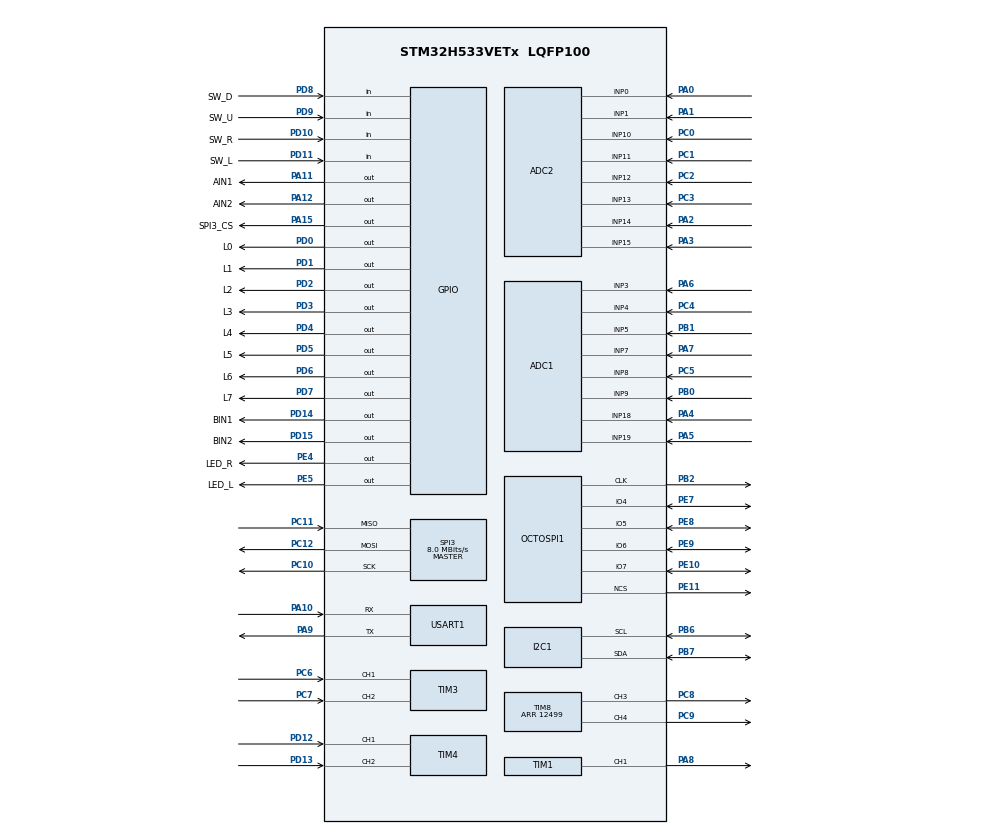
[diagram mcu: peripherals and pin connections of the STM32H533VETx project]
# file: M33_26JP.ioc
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ADC1.Channel-0\#ChannelRegularConversion=ADC_CHANNEL_5
ADC1.Channel-1\#ChannelRegularConversion=ADC_CHANNEL_9
ADC1.Channel-2\#ChannelRegularConversion=ADC_CHANNEL_8
ADC1.Channel-3\#ChannelRegularConversion=ADC_CHANNEL_4
ADC1.Channel-4\#ChannelRegularConversion=ADC_CHANNEL_7
ADC1.Channel-5\#ChannelRegularConversion=ADC_CHANNEL_3
ADC1.Channel-6\#ChannelRegularConversion=ADC_CHANNEL_19
ADC1.Channel-7\#ChannelRegularConversion=ADC_CHANNEL_18
ADC1.DiscontinuousConvMode=ENABLE
ADC1.ExternalTrigConv=ADC_EXTERNALTRIG_T2_TRGO
ADC1.MonitoredBy-0\#ChannelRegularConversion=__NULL
ADC1.MonitoredBy-1\#ChannelRegularConversion=__NULL
ADC1.MonitoredBy-2\#ChannelRegularConversion=__NULL
ADC1.MonitoredBy-3\#ChannelRegularConversion=__NULL
ADC1.MonitoredBy-4\#ChannelRegularConversion=__NULL
ADC1.MonitoredBy-5\#ChannelRegularConversion=__NULL
ADC1.MonitoredBy-6\#ChannelRegularConversion=__NULL
ADC1.MonitoredBy-7\#ChannelRegularConversion=__NULL
ADC1.NbrOfConversion=8
ADC1.NbrOfConversionFlag=1
ADC1.OffsetNumber-0\#ChannelRegularConversion=ADC_OFFSET_NONE
ADC1.OffsetNumber-1\#ChannelRegularConversion=ADC_OFFSET_NONE
ADC1.OffsetNumber-2\#ChannelRegularConversion=ADC_OFFSET_NONE
ADC1.OffsetNumber-3\#ChannelRegularConversion=ADC_OFFSET_NONE
ADC1.OffsetNumber-4\#ChannelRegularConversion=ADC_OFFSET_NONE
ADC1.OffsetNumber-5\#ChannelRegularConversion=ADC_OFFSET_NONE
ADC1.OffsetNumber-6\#ChannelRegularConversion=ADC_OFFSET_NONE
ADC1.OffsetNumber-7\#ChannelRegularConversion=ADC_OFFSET_NONE
ADC1.Rank-0\#ChannelRegularConversion=1
ADC1.Rank-1\#ChannelRegularConversion=2
ADC1.Rank-2\#ChannelRegularConversion=3
ADC1.Rank-3\#ChannelRegularConversion=4
ADC1.Rank-4\#ChannelRegularConversion=5
ADC1.Rank-5\#ChannelRegularConversion=6
ADC1.Rank-6\#ChannelRegularConversion=7
ADC1.Rank-7\#ChannelRegularConversion=8
ADC1.SamplingTime-0\#ChannelRegularConversion=ADC_SAMPLETIME_6CYCLES_5
ADC1.SamplingTime-1\#ChannelRegularConversion=ADC_SAMPLETIME_6CYCLES_5
ADC1.SamplingTime-2\#ChannelRegularConversion=ADC_SAMPLETIME_6CYCLES_5
ADC1.SamplingTime-3\#ChannelRegularConversion=ADC_SAMPLETIME_6CYCLES_5
ADC1.SamplingTime-4\#ChannelRegularConversion=ADC_SAMPLETIME_6CYCLES_5
ADC1.SamplingTime-5\#ChannelRegularConversion=ADC_SAMPLETIME_6CYCLES_5
ADC1.SamplingTime-6\#ChannelRegularConversion=ADC_SAMPLETIME_6CYCLES_5
ADC1.SamplingTime-7\#ChannelRegularConversion=ADC_SAMPLETIME_6CYCLES_5
ADC1.master=1
ADC2.Channel-2\#ChannelRegularConversion=ADC_CHANNEL_15
ADC2.Channel-3\#ChannelRegularConversion=ADC_CHANNEL_14
ADC2.Channel-4\#ChannelRegularConversion=ADC_CHANNEL_1
ADC2.Channel-5\#ChannelRegularConversion=ADC_CHANNEL_0
ADC2.Channel-6\#ChannelRegularConversion=ADC_CHANNEL_13
ADC2.Channel-7\#ChannelRegularConversion=ADC_CHANNEL_12
ADC2.Channel-8\#ChannelRegularConversion=ADC_CHANNEL_11
ADC2.Channel-9\#ChannelRegularConversion=ADC_CHANNEL_10
ADC2.DiscontinuousConvMode=ENABLE
ADC2.ExternalTrigConv=ADC_EXTERNALTRIG_T2_TRGO
ADC2.MonitoredBy-2\#ChannelRegularConversion=__NULL
ADC2.MonitoredBy-3\#ChannelRegularConversion=__NULL
ADC2.MonitoredBy-4\#ChannelRegularConversion=__NULL
ADC2.MonitoredBy-5\#ChannelRegularConversion=__NULL
ADC2.MonitoredBy-6\#ChannelRegularConversion=__NULL
ADC2.MonitoredBy-7\#ChannelRegularConversion=__NULL
ADC2.MonitoredBy-8\#ChannelRegularConversion=__NULL
ADC2.MonitoredBy-9\#ChannelRegularConversion=__NULL
ADC2.NbrOfConversion=8
ADC2.NbrOfConversionFlag=1
ADC2.OffsetNumber-2\#ChannelRegularConversion=ADC_OFFSET_NONE
ADC2.OffsetNumber-3\#ChannelRegularConversion=ADC_OFFSET_NONE
ADC2.OffsetNumber-4\#ChannelRegularConversion=ADC_OFFSET_NONE
ADC2.OffsetNumber-5\#ChannelRegularConversion=ADC_OFFSET_NONE
ADC2.OffsetNumber-6\#ChannelRegularConversion=ADC_OFFSET_NONE
ADC2.OffsetNumber-7\#ChannelRegularConversion=ADC_OFFSET_NONE
ADC2.OffsetNumber-8\#ChannelRegularConversion=ADC_OFFSET_NONE
ADC2.OffsetNumber-9\#ChannelRegularConversion=ADC_OFFSET_NONE
ADC2.Rank-2\#ChannelRegularConversion=1
ADC2.Rank-3\#ChannelRegularConversion=2
ADC2.Rank-4\#ChannelRegularConversion=3
ADC2.Rank-5\#ChannelRegularConversion=4
ADC2.Rank-6\#ChannelRegularConversion=5
ADC2.Rank-7\#ChannelRegularConversion=6
ADC2.Rank-8\#ChannelRegularConversion=7
ADC2.Rank-9\#ChannelRegularConversion=8
ADC2.SamplingTime-2\#ChannelRegularConversion=ADC_SAMPLETIME_6CYCLES_5
ADC2.SamplingTime-3\#ChannelRegularConversion=ADC_SAMPLETIME_6CYCLES_5
ADC2.SamplingTime-4\#ChannelRegularConversion=ADC_SAMPLETIME_6CYCLES_5
ADC2.SamplingTime-5\#ChannelRegularConversion=ADC_SAMPLETIME_6CYCLES_5
ADC2.SamplingTime-6\#ChannelRegularConversion=ADC_SAMPLETIME_6CYCLES_5
ADC2.SamplingTime-7\#ChannelRegularConversion=ADC_SAMPLETIME_6CYCLES_5
ADC2.SamplingTime-8\#ChannelRegularConversion=ADC_SAMPLETIME_6CYCLES_5
ADC2.SamplingTime-9\#ChannelRegularConversion=ADC_SAMPLETIME_6CYCLES_5
BOOTPATH.BootPathName=LEGACY
BOOTPATH.UserSelectedBootPath=LEGACY
CORTEX_M33_NS.Number-Cortex_Memory_Protection_Unit_Region0_OTP_RO_AREAS_Settings=MPU_REGION_NUMBER0
CORTEX_M33_NS.default_mode_Activation=1
CORTEX_M33_NS.userName=CORTEX_M33
I2C1.Timing=0x60808CD3
Mcu.Family=STM32H5
Mcu.Name=STM32H533VETx
Mcu.Package=LQFP100
NVIC.ADC2_IRQn=true\:0\:0\:false\:false\:true\:true\:true\:true
NVIC.PriorityGroup=NVIC_PRIORITYGROUP_4
NVIC.TIM2_IRQn=true\:2\:0\:true\:false\:true\:true\:true\:true
NVIC.TIM6_IRQn=true\:1\:0\:true\:false\:true\:true\:true\:true
OCTOSPI1.ChipSelectHighTimeCycle=2
OCTOSPI1.ClockPrescaler=4
OCTOSPI1.MemorySize=HAL_XSPI_SIZE_64MB
PA0.Signal=ADCx_INP0
PA1.Signal=ADCx_INP1
PA10.Mode=Asynchronous
PA10.Signal=USART1_RX
PA11.GPIO_Label=AIN1
PA11.Signal=GPIO_Output
PA12.GPIO_Label=AIN2
PA12.Signal=GPIO_Output
PA13(JTMS/SWDIO).Mode=Serial_Wire
PA13(JTMS/SWDIO).Signal=DEBUG_JTMS-SWDIO
PA14(JTCK/SWCLK).Mode=Serial_Wire
PA14(JTCK/SWCLK).Signal=DEBUG_JTCK-SWCLK
PA15(JTDI).GPIO_Label=SPI3_CS
PA15(JTDI).GPIO_PuPd=GPIO_PULLUP
PA15(JTDI).PinState=GPIO_PIN_SET
PA15(JTDI).Signal=GPIO_Output
PA2.Signal=ADCx_INP14
PA3.Signal=ADCx_INP15
PA4.Signal=ADCx_INP18
PA5.Signal=ADCx_INP19
PA6.Signal=ADCx_INP3
PA7.Signal=ADCx_INP7
PA8.Signal=S_TIM1_CH1
PA9.Mode=Asynchronous
PA9.Signal=USART1_TX
PB0.Signal=ADCx_INP9
PB1.Signal=ADCx_INP5
PB2.Mode=quad_mode
PB2.Signal=OCTOSPI1_CLK
PB6.Mode=I2C
PB6.Signal=I2C1_SCL
PB7.Mode=I2C
PB7.Signal=I2C1_SDA
PC0.Signal=ADCx_INP10
PC1.Signal=ADCx_INP11
PC10.Mode=Full_Duplex_Master
PC10.Signal=SPI3_SCK
PC11.Mode=Full_Duplex_Master
PC11.Signal=SPI3_MISO
PC12.Mode=Full_Duplex_Master
PC12.Signal=SPI3_MOSI
PC2.Signal=ADCx_INP12
PC3.Signal=ADCx_INP13
PC4.Signal=ADCx_INP4
PC5.Signal=ADCx_INP8
PC6.Signal=S_TIM3_CH1
PC7.Signal=S_TIM3_CH2
PC8.Signal=S_TIM8_CH3
PC9.Signal=S_TIM8_CH4
PD0.GPIO_Label=L0
PD0.Signal=GPIO_Output
PD1.GPIO_Label=L1
PD1.Signal=GPIO_Output
PD10.GPIO_Label=SW_R
PD10.GPIO_PuPd=GPIO_PULLUP
PD10.Signal=GPIO_Input
PD11.GPIO_Label=SW_L
PD11.GPIO_PuPd=GPIO_PULLUP
PD11.Signal=GPIO_Input
PD12.Signal=S_TIM4_CH1
PD13.Signal=S_TIM4_CH2
PD14.GPIO_Label=BIN1
PD14.Signal=GPIO_Output
PD15.GPIO_Label=BIN2
PD15.Signal=GPIO_Output
PD2.GPIO_Label=L2
PD2.Signal=GPIO_Output
PD3.GPIO_Label=L3
PD3.Signal=GPIO_Output
PD4.GPIO_Label=L4
PD4.Signal=GPIO_Output
PD5.GPIO_Label=L5
PD5.Signal=GPIO_Output
PD6.GPIO_Label=L6
PD6.Signal=GPIO_Output
PD7.GPIO_Label=L7
PD7.Signal=GPIO_Output
PD8.GPIO_Label=SW_D
PD8.GPIO_PuPd=GPIO_PULLUP
PD8.Signal=GPIO_Input
PD9.GPIO_Label=SW_U
PD9.GPIO_PuPd=GPIO_PULLUP
PD9.Signal=GPIO_Input
PE10.Mode=OCTOSPI1_IO[7\:4]
PE10.Signal=OCTOSPI1_IO7
PE11.Mode=quad_mode
PE11.Signal=OCTOSPI1_NCS
PE4.GPIO_Label=LED_R
PE4.Signal=GPIO_Output
PE5.GPIO_Label=LED_L
PE5.Signal=GPIO_Output
PE7.Mode=OCTOSPI1_IO[7\:4]
PE7.Signal=OCTOSPI1_IO4
PE8.Mode=OCTOSPI1_IO[7\:4]
PE8.Signal=OCTOSPI1_IO5
PE9.Mode=OCTOSPI1_IO[7\:4]
PE9.Signal=OCTOSPI1_IO6
PH0-OSC_IN(PH0).Mode=HSE-External-Clock-Source
PH0-OSC_IN(PH0).Signal=RCC_OSC_IN
PWR.pwrPrivilege=PWR_PRIVILEGE_YES
ProjectManager.HeapSize=0x200
ProjectManager.StackSize=0x400
ProjectManager.TargetToolchain=CMake
RCC.ADCFreq_Value=250000000
RCC.AHBFreq_Value=250000000
RCC.APB1Freq_Value=250000000
RCC.APB1TimFreq_Value=250000000
RCC.APB2Freq_Value=250000000
RCC.APB2TimFreq_Value=250000000
RCC.APB3Freq_Value=250000000
RCC.CSI_VALUE=4000000
RCC.CortexFreq_Value=250000000
RCC.EPOD_VALUE=20000000
RCC.HCLKFreq_Value=250000000
RCC.HSE_VALUE=20000000
RCC.HSI48_VALUE=48000000
RCC.HSI_VALUE=64000000
RCC.LSE_VALUE=32768
RCC.LSIRC_VALUE=32000
RCC.PLL1Q=3
RCC.PLL2FRACN=0
RCC.PLL3FRACN=0
RCC.PLLFRACN=0
RCC.PLLM=2
RCC.PLLN=50
RCC.PLLSourceVirtual=RCC_PLL1_SOURCE_HSE
RCC.SPI3CLockSelection=RCC_SPI3CLKSOURCE_CLKP
RCC.SYSCLKFreq_VALUE=250000000
RCC.SYSCLKSource=RCC_SYSCLKSOURCE_PLLCLK
RCC.USBFreq_Value=48000000
RCC.VCOOutputFreq_Value=500000000
SH.ADCx_INP0.0=ADC2_INP0,IN0-Single-Ended
SH.ADCx_INP1.0=ADC2_INP1,IN1-Single-Ended
SH.ADCx_INP10.0=ADC2_INP10,IN10-Single-Ended
SH.ADCx_INP11.0=ADC2_INP11,IN11-Single-Ended
SH.ADCx_INP12.0=ADC2_INP12,IN12-Single-Ended
SH.ADCx_INP13.0=ADC2_INP13,IN13-Single-Ended
SH.ADCx_INP14.0=ADC2_INP14,IN14-Single-Ended
SH.ADCx_INP15.0=ADC2_INP15,IN15-Single-Ended
SH.ADCx_INP18.0=ADC1_INP18,IN18-Single-Ended
SH.ADCx_INP19.0=ADC1_INP19,IN19-Single-Ended
SH.ADCx_INP3.0=ADC1_INP3,IN3-Single-Ended
SH.ADCx_INP4.0=ADC1_INP4,IN4-Single-Ended
SH.ADCx_INP5.0=ADC1_INP5,IN5-Single-Ended
SH.ADCx_INP7.0=ADC1_INP7,IN7-Single-Ended
SH.ADCx_INP8.0=ADC1_INP8,IN8-Single-Ended
SH.ADCx_INP9.0=ADC1_INP9,IN9-Single-Ended
SH.S_TIM1_CH1.0=TIM1_CH1,PWM Generation1 CH1
SH.S_TIM3_CH1.0=TIM3_CH1,Encoder_Interface
SH.S_TIM3_CH2.0=TIM3_CH2,Encoder_Interface
SH.S_TIM4_CH1.0=TIM4_CH1,Encoder_Interface
SH.S_TIM4_CH2.0=TIM4_CH2,Encoder_Interface
SH.S_TIM8_CH3.0=TIM8_CH3,PWM Generation3 CH3
SH.S_TIM8_CH4.0=TIM8_CH4,PWM Generation4 CH4
SPI3.BaudRatePrescaler=SPI_BAUDRATEPRESCALER_4
SPI3.CalculateBaudRate=8.0 MBits/s
SPI3.DataSize=SPI_DATASIZE_8BIT
SPI3.Direction=SPI_DIRECTION_2LINES
SPI3.Mode=SPI_MODE_MASTER
SPI3.VirtualType=VM_MASTER
TIM1.Channel-PWM\ Generation1\ CH1=TIM_CHANNEL_1
TIM1.PeriodNoDither=19999
TIM1.Prescaler=249
TIM1.PulseNoDither_1=1000
TIM2.Channel-PWM\ Generation2\ No\ Output=TIM_CHANNEL_2
TIM2.OCMode_PWM-PWM\ Generation2\ No\ Output=TIM_OCMODE_PWM2
TIM2.PeriodNoDither=49
TIM2.Prescaler=124
TIM2.PulseNoDither_2=25
TIM2.TIM_MasterOutputTrigger=TIM_TRGO_OC2REF
TIM6.PeriodNoDither=499
TIM6.Prescaler=249
TIM8.Channel-PWM\ Generation3\ CH3=TIM_CHANNEL_3
TIM8.Channel-PWM\ Generation4\ CH4=TIM_CHANNEL_4
TIM8.PeriodNoDither=12499
USART1.SwapParam=ADVFEATURE_SWAP_ENABLE
USART1.VirtualMode-Asynchronous=VM_ASYNC
VP_BOOTPATH_VS_BOOTPATH.Mode=BP_Activate
VP_CORTEX_M33_NS_VS_Hclk.Mode=Hclk_Mode
VP_ICACHE_VS_ICACHE.Mode=DirectMappedCache
VP_MEMORYMAP_VS_MEMORYMAP.Mode=CurAppReg
VP_PWR_VS_LPOM.Mode=PowerOptimisation
VP_PWR_VS_SECSignals.Mode=Security/Privilege
VP_TIM1_VS_ClockSourceINT.Mode=Internal
VP_TIM2_VS_ClockSourceINT.Mode=Internal
VP_TIM2_VS_no_output2.Mode=PWM Generation2 No Output
VP_TIM6_VS_ClockSourceINT.Mode=Enable_Timer
VP_TIM8_VS_ClockSourceINT.Mode=Internal
board=custom

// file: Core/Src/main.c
/* USER CODE BEGIN Header */
/**
  ******************************************************************************
  * @file           : main.c
  * @brief          : Main program body
  ******************************************************************************
  * @attention
  *
  * Copyright (c) 2026 STMicroelectronics.
  * All rights reserved.
  *
  * This software is licensed under terms that can be found in the LICENSE file
  * in the root directory of this software component.
  * If no LICENSE file comes with this software, it is provided AS-IS.
  *
  ******************************************************************************
  */
/* USER CODE END Header */
#include "main.h"
#include "adc.h"
#include "i2c.h"
#include "icache.h"
#include "octospi.h"
#include "spi.h"
#include "tim.h"
#include "usart.h"
#include "gpio.h"

/* USER CODE BEGIN Includes */
#include "motor.h"
#include "menu.h"
#include "search.h"
#include "sensor.h"
#include "gyro.h"
#include "rom.h"
#include "variable.h"

/* USER CODE END Includes */

void SystemClock_Config(void);
void PeriphCommonClock_Config(void);
static void MPU_Config(void);

int main(void)
{

  /* MCU Configuration--------------------------------------------------------*/

  /* MPU Configuration--------------------------------------------------------*/
  MPU_Config();

  /* Reset of all peripherals, Initializes the Flash interface and the Systick. */
  HAL_Init();

  /** PWR Privilege Configuration
  */
  LL_PWR_EnableNSecurePrivilege();

  /* Configure the system clock */
  SystemClock_Config();

  /* Configure the peripherals common clocks */
  PeriphCommonClock_Config();

  /* Initialize all configured peripherals */
  MX_GPIO_Init();
  MX_TIM1_Init();
  suction_esc_calibration();
  MX_ADC1_Init();
  MX_ADC2_Init();
  MX_I2C1_Init();
  MX_ICACHE_Init();
  MX_OCTOSPI1_Init();
  MX_SPI3_Init();
  MX_TIM3_Init();
  MX_TIM4_Init();
  MX_TIM8_Init();
  MX_USART1_UART_Init();
  MX_TIM2_Init();
  MX_TIM6_Init();
  /* USER CODE BEGIN 2 */
  Variable_Init();
  sen_vari_init();
  rom_load_all();
  motor_init();
  LSM6DSR_Init();
  menu_start();

  /* USER CODE END 2 */

  /* Infinite loop */
  while (1)
  {

  }
}

void SystemClock_Config(void)
{
  LL_FLASH_SetLatency(LL_FLASH_LATENCY_5);
  while(LL_FLASH_GetLatency()!= LL_FLASH_LATENCY_5)
  {
  }

  LL_PWR_SetRegulVoltageScaling(LL_PWR_REGU_VOLTAGE_SCALE0);
  while (LL_PWR_IsActiveFlag_VOS() == 0)
  {
  }
  LL_RCC_HSE_EnableBypass();
  LL_RCC_HSE_SetExternalClockType(LL_RCC_HSE_ANALOG_TYPE);
  LL_RCC_HSE_Enable();

   /* Wait till HSE is ready */
  while(LL_RCC_HSE_IsReady() != 1)
  {
  }

  LL_RCC_HSI_Enable();

   /* Wait till HSI is ready */
  while(LL_RCC_HSI_IsReady() != 1)
  {
  }

  LL_RCC_HSI_SetCalibTrimming(64);
  LL_RCC_HSI_SetDivider(LL_RCC_HSI_DIV_2);
  LL_RCC_PLL1_SetSource(LL_RCC_PLL1SOURCE_HSE);
  LL_RCC_PLL1_SetVCOInputRange(LL_RCC_PLLINPUTRANGE_8_16);
  LL_RCC_PLL1_SetVCOOutputRange(LL_RCC_PLLVCORANGE_WIDE);
  LL_RCC_PLL1_SetM(2);
  LL_RCC_PLL1_SetN(50);
  LL_RCC_PLL1_SetP(2);
  LL_RCC_PLL1_SetQ(3);
  LL_RCC_PLL1_SetR(2);
  LL_RCC_PLL1P_Enable();
  LL_RCC_PLL1_Enable();

   /* Wait till PLL is ready */
  while(LL_RCC_PLL1_IsReady() != 1)
  {
  }

  LL_RCC_SetSysClkSource(LL_RCC_SYS_CLKSOURCE_PLL1);

   /* Wait till System clock is ready */
  while(LL_RCC_GetSysClkSource() != LL_RCC_SYS_CLKSOURCE_STATUS_PLL1)
  {
  }

  LL_RCC_SetAHBPrescaler(LL_RCC_SYSCLK_DIV_1);
  LL_RCC_SetAPB1Prescaler(LL_RCC_APB1_DIV_1);
  LL_RCC_SetAPB2Prescaler(LL_RCC_APB2_DIV_1);
  LL_RCC_SetAPB3Prescaler(LL_RCC_APB3_DIV_1);
  LL_SetSystemCoreClock(250000000);

   /* Update the time base */
  if (HAL_InitTick (TICK_INT_PRIORITY) != HAL_OK)
  {
    Error_Handler();
  }
}

void PeriphCommonClock_Config(void)
{
  LL_RCC_SetCLKPClockSource(LL_RCC_CLKP_CLKSOURCE_HSI);
}

 /* MPU Configuration */

void MPU_Config(void)
{

  /* Disables the MPU */
  LL_MPU_Disable();

  /** Initializes and configures the Region 0 and the memory to be protected
  */
  LL_MPU_ConfigRegion(LL_MPU_REGION_NUMBER0, LL_MPU_REGION_ALL_RO|LL_MPU_INSTRUCTION_ACCESS_DISABLE|LL_MPU_ACCESS_NOT_SHAREABLE, LL_MPU_ATTRIBUTES_NUMBER0, 0x08FFF000, 0x08FFFFFF);
  LL_MPU_EnableRegion(LL_MPU_REGION_NUMBER0);

  /** Initializes and configures the Attribute 0 and the memory to be protected
  */
  LL_MPU_ConfigAttributes(LL_MPU_ATTRIBUTES_NUMBER0, LL_MPU_NOT_CACHEABLE);
  /* Enables the MPU */
  LL_MPU_Enable(LL_MPU_CTRL_PRIVILEGED_DEFAULT);

}

void Error_Handler(void)
{
  __disable_irq();
  while (1)
  {
  }
}
